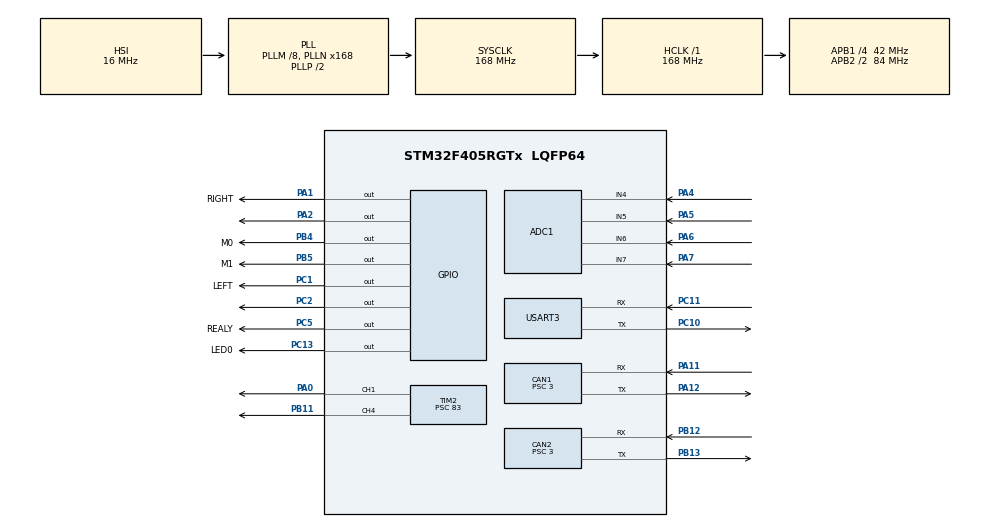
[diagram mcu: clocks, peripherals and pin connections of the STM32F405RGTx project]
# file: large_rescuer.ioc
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PC13-ANTI_TAMP.GPIO_Speed=GPIO_SPEED_FREQ_LOW
Mcu.Family=STM32F4
NVIC.USART3_IRQn=true\:7\:0\:true\:false\:true\:true\:true
PA2.GPIO_PuPd=GPIO_PULLUP
PH0-OSC_IN.Signal=RCC_OSC_IN
RCC.CortexFreq_Value=168000000
ADC1.ContinuousConvMode=ENABLE
CAN2.CalculateTimeBit=999.99
PC10.Signal=USART3_TX
PA2.GPIO_Speed=GPIO_SPEED_FREQ_HIGH
PA11.Mode=CAN_Activate
PC2.GPIO_Speed=GPIO_SPEED_FREQ_HIGH
PB11.Signal=S_TIM2_CH4
PB13.Signal=CAN2_TX
RCC.SYSCLKSource=RCC_SYSCLKSOURCE_PLLCLK
ProjectManager.StackSize=0x400
PA12.Signal=CAN1_TX
ADC1.Channel-3\#ChannelRegularConversion=ADC_CHANNEL_7
RCC.HCLKFreq_Value=168000000
RCC.APB2TimFreq_Value=168000000
Dma.ADC1.0.Direction=DMA_PERIPH_TO_MEMORY
ADC1.Channel-2\#ChannelRegularConversion=ADC_CHANNEL_6
NVIC.DMA2_Stream0_IRQn=true\:0\:0\:false\:false\:true\:false\:true
PC1.PinState=GPIO_PIN_SET
PA1.GPIO_PuPd=GPIO_PULLUP
Dma.ADC1.0.MemDataAlignment=DMA_MDATAALIGN_HALFWORD
RCC.AHBFreq_Value=168000000
PH0-OSC_IN.Mode=HSE-External-Oscillator
ADC1.Channel-0\#ChannelRegularConversion=ADC_CHANNEL_4
RCC.HSE_VALUE=25000000
ADC1.ScanConvMode=ENABLE
PC1.GPIO_PuPd=GPIO_PULLUP
PC13-ANTI_TAMP.Signal=GPIO_Output
PA2.PinState=GPIO_PIN_SET
ADC1.Rank-2\#ChannelRegularConversion=3
PA14.Mode=Serial_Wire
CAN2.Prescaler=3
Dma.ADC1.0.PeriphInc=DMA_PINC_DISABLE
TIM2.Channel-PWM\ Generation1\ CH1=TIM_CHANNEL_1
TIM4.Period=41999
ADC1.SamplingTime-0\#ChannelRegularConversion=ADC_SAMPLETIME_144CYCLES
PH1-OSC_OUT.Mode=HSE-External-Oscillator
CAN1.Prescaler=3
Mcu.Package=LQFP64
TIM2.Prescaler=83
PA6.Signal=ADCx_IN6
PB12.Mode=CAN_Activate
CAN2.BS1=CAN_BS1_7TQ
CAN2.BS2=CAN_BS2_6TQ
PA1.PinState=GPIO_PIN_SET
PC11.Mode=Asynchronous
PB5.GPIO_Speed=GPIO_SPEED_FREQ_HIGH
RCC.APB2CLKDivider=RCC_HCLK_DIV2
PB5.GPIO_Label=M1
RCC.APB1TimFreq_Value=84000000
Dma.ADC1.0.FIFOMode=DMA_FIFOMODE_DISABLE
PC5.Signal=GPIO_Output
PB13.Mode=CAN_Activate
Dma.Request0=ADC1
CAN1.CalculateTimeBit=999.99
PB4.Signal=GPIO_Output
CAN1.CalculateTimeQuantum=71.42857142857143
CAN2.CalculateBaudRate=1000000
TIM2.Channel-PWM\ Generation4\ CH4=TIM_CHANNEL_4
TIM4.AutoReloadPreload=TIM_AUTORELOAD_PRELOAD_ENABLE
Dma.ADC1.0.Instance=DMA2_Stream0
ADC1.Rank-0\#ChannelRegularConversion=1
PC13-ANTI_TAMP.GPIO_PuPd=GPIO_PULLDOWN
SH.ADCx_IN6.0=ADC1_IN6,IN6
PC13-ANTI_TAMP.GPIO_Label=LED0
PC11.Signal=USART3_RX
CAN1.CalculateBaudRate=1000000
PC2.Signal=GPIO_Output
PC10.Mode=Asynchronous
RCC.APB1CLKDivider=RCC_HCLK_DIV4
PC5.GPIO_PuPd=GPIO_PULLDOWN
NVIC.CAN2_RX1_IRQn=true\:3\:0\:true\:false\:true\:true\:true
ADC1.SamplingTime-2\#ChannelRegularConversion=ADC_SAMPLETIME_144CYCLES
PC13-ANTI_TAMP.PinState=GPIO_PIN_SET
PA0-WKUP.Signal=S_TIM2_CH1_ETR
TIM2.Pulse-PWM\ Generation1\ CH1=50
PA13.Signal=SYS_JTMS-SWDIO
Dma.ADC1.0.PeriphDataAlignment=DMA_PDATAALIGN_HALFWORD
CAN1.BS2=CAN_BS2_6TQ
CAN1.BS1=CAN_BS1_7TQ
ProjectManager.TargetToolchain=STM32CubeIDE
SH.ADCx_IN7.0=ADC1_IN7,IN7
Dma.ADC1.0.Mode=DMA_CIRCULAR
Dma.ADC1.0.Priority=DMA_PRIORITY_LOW
ADC1.Channel-1\#ChannelRegularConversion=ADC_CHANNEL_5
PB4.GPIO_PuPd=GPIO_PULLDOWN
TIM4.Prescaler=29
RCC.LSE_VALUE=32768
PA1.Signal=GPIO_Output
PA5.Signal=ADCx_IN5
board=custom
RCC.VCOOutputFreq_Value=336000000
PB4.GPIO_Speed=GPIO_SPEED_FREQ_HIGH
RCC.APB2Freq_Value=84000000
PB4.GPIO_Label=M0
VP_TIM2_VS_ClockSourceINT.Mode=Internal
PA1.GPIO_Speed=GPIO_SPEED_FREQ_HIGH
PC1.GPIO_Label=LEFT
PA1.GPIO_Label=RIGHT
CAN2.CalculateTimeQuantum=71.42857142857143
PH1-OSC_OUT.Signal=RCC_OSC_OUT
PC1.GPIO_Speed=GPIO_SPEED_FREQ_HIGH
SH.ADCx_IN4.0=ADC1_IN4,IN4
PC2.GPIO_PuPd=GPIO_PULLUP
ADC1.DMAContinuousRequests=ENABLE
TIM2.Period=499
ADC1.NbrOfConversion=4
PA13.Mode=Serial_Wire
Mcu.Name=STM32F405RGTx
PA2.Signal=GPIO_Output
CAN1.SJW=CAN_SJW_1TQ
RCC.48MHZClocksFreq_Value=84000000
PA4.Signal=ADCx_IN4
ADC1.SamplingTime-1\#ChannelRegularConversion=ADC_SAMPLETIME_144CYCLES
RCC.SYSCLKFreq_VALUE=168000000
PB5.Signal=GPIO_Output
ADC1.master=1
PA12.Mode=CAN_Activate
PC2.PinState=GPIO_PIN_SET
ADC1.SamplingTime-3\#ChannelRegularConversion=ADC_SAMPLETIME_144CYCLES
ADC1.Rank-3\#ChannelRegularConversion=4
PC5.GPIO_Label=REALY
USART3.VirtualMode=VM_ASYNC
PB5.GPIO_PuPd=GPIO_PULLDOWN
ADC1.Rank-1\#ChannelRegularConversion=2
PA11.Signal=CAN1_RX
SH.S_TIM2_CH1_ETR.0=TIM2_CH1,PWM Generation1 CH1
PA14.Signal=SYS_JTCK-SWCLK
Dma.ADC1.0.MemInc=DMA_MINC_ENABLE
ProjectManager.HeapSize=0x200
SH.S_TIM2_CH4.0=TIM2_CH4,PWM Generation4 CH4
RCC.HSI_VALUE=16000000
SH.ADCx_IN5.0=ADC1_IN5,IN5
VP_TIM4_VS_ClockSourceINT.Mode=Internal
NVIC.PriorityGroup=NVIC_PRIORITYGROUP_4
ADC1.NbrOfConversionFlag=1
PC5.GPIO_Speed=GPIO_SPEED_FREQ_HIGH
RCC.PLLM=8
RCC.PLLN=168
TIM2.AutoReloadPreload=TIM_AUTORELOAD_PRELOAD_ENABLE
TIM2.Pulse-PWM\ Generation4\ CH4=50
NVIC.TIM4_IRQn=true\:2\:0\:true\:false\:true\:true\:true
RCC.APB1Freq_Value=42000000
ADC1.ClockPrescaler=ADC_CLOCK_SYNC_PCLK_DIV8
PC1.Signal=GPIO_Output
PB12.Signal=CAN2_RX
NVIC.CAN1_RX0_IRQn=true\:1\:0\:true\:false\:true\:true\:true
PA7.Signal=ADCx_IN7

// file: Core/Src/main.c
/* USER CODE BEGIN Header */
/**
 ******************************************************************************
 * @file           : main.c
 * @brief          : Main program body
 ******************************************************************************
 * @attention
 *
 * <h2><center>&copy; Copyright (c) 2021 STMicroelectronics.
 * All rights reserved.</center></h2>
 *
 * This software component is licensed by ST under BSD 3-Clause license,
 * the "License"; You may not use this file except in compliance with the
 * License. You may obtain a copy of the License at:
 *                        opensource.org/licenses/BSD-3-Clause
 *
 ******************************************************************************
 */
/* USER CODE END Header */
#include "main.h"
#include "adc.h"
#include "can.h"
#include "dma.h"
#include "tim.h"
#include "usart.h"
#include "gpio.h"

void SystemClock_Config(void);

int main(void)
{

  /* MCU Configuration--------------------------------------------------------*/

  /* Reset of all peripherals, Initializes the Flash interface and the Systick. */
  HAL_Init();

  /* Configure the system clock */
  SystemClock_Config();

  /* Initialize all configured peripherals */
  MX_GPIO_Init();
  MX_DMA_Init();
  MX_ADC1_Init();
  MX_CAN1_Init();
  MX_CAN2_Init();
  MX_TIM4_Init();
  MX_USART3_UART_Init();
  MX_TIM2_Init();
  /* USER CODE BEGIN 2 */
	Control_Initialize();
	printf("start\r\n");
	Subtrack_Rest(); //���Ĵ���λ
  /* USER CODE END 2 */

  /* Infinite loop */
  /* USER CODE BEGIN WHILE */
	while (1)
	{
//		HAL_IWDG_Refresh(&hiwdg);

		debug();
		Angle_Position_Control();
		HAL_GPIO_TogglePin(LED0_GPIO_Port, LED0_Pin);
    /* USER CODE END WHILE */

	}
}

void SystemClock_Config(void)
{
  RCC_OscInitTypeDef RCC_OscInitStruct = {0};
  RCC_ClkInitTypeDef RCC_ClkInitStruct = {0};

  /** Configure the main internal regulator output voltage
  */
  __HAL_RCC_PWR_CLK_ENABLE();
  __HAL_PWR_VOLTAGESCALING_CONFIG(PWR_REGULATOR_VOLTAGE_SCALE1);
  /** Initializes the RCC Oscillators according to the specified parameters
  * in the RCC_OscInitTypeDef structure.
  */
  RCC_OscInitStruct.OscillatorType = RCC_OSCILLATORTYPE_HSI;
  RCC_OscInitStruct.HSIState = RCC_HSI_ON;
  RCC_OscInitStruct.HSICalibrationValue = RCC_HSICALIBRATION_DEFAULT;
  RCC_OscInitStruct.PLL.PLLState = RCC_PLL_ON;
  RCC_OscInitStruct.PLL.PLLSource = RCC_PLLSOURCE_HSI;
  RCC_OscInitStruct.PLL.PLLM = 8;
  RCC_OscInitStruct.PLL.PLLN = 168;
  RCC_OscInitStruct.PLL.PLLP = RCC_PLLP_DIV2;
  RCC_OscInitStruct.PLL.PLLQ = 4;
  if (HAL_RCC_OscConfig(&RCC_OscInitStruct) != HAL_OK)
  {
    Error_Handler();
  }
  /** Initializes the CPU, AHB and APB buses clocks
  */
  RCC_ClkInitStruct.ClockType = RCC_CLOCKTYPE_HCLK|RCC_CLOCKTYPE_SYSCLK
                              |RCC_CLOCKTYPE_PCLK1|RCC_CLOCKTYPE_PCLK2;
  RCC_ClkInitStruct.SYSCLKSource = RCC_SYSCLKSOURCE_PLLCLK;
  RCC_ClkInitStruct.AHBCLKDivider = RCC_SYSCLK_DIV1;
  RCC_ClkInitStruct.APB1CLKDivider = RCC_HCLK_DIV4;
  RCC_ClkInitStruct.APB2CLKDivider = RCC_HCLK_DIV2;

  if (HAL_RCC_ClockConfig(&RCC_ClkInitStruct, FLASH_LATENCY_5) != HAL_OK)
  {
    Error_Handler();
  }
}

void Error_Handler(void)
{
  /* USER CODE BEGIN Error_Handler_Debug */
	/* User can add his own implementation to report the HAL error return state */
	__disable_irq();
	while (1)
	{
		printf("Error\r\n");
	}
  /* USER CODE END Error_Handler_Debug */
}

/************************ (C) COPYRIGHT STMicroelectronics *****END OF FILE****/
